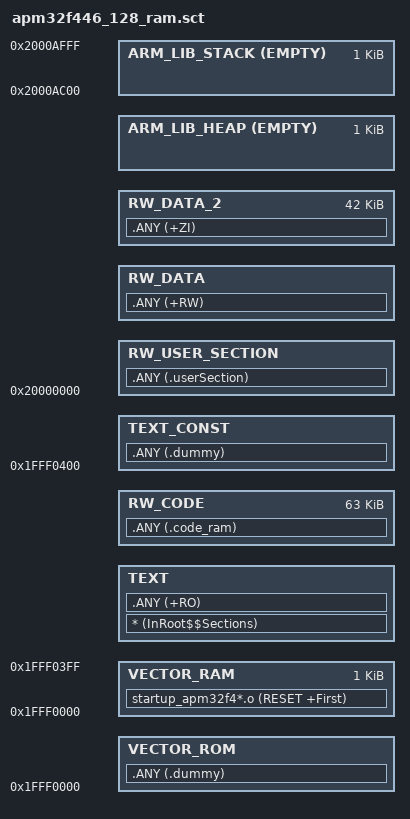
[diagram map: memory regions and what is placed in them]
#! armclang --target=arm-arm-none-eabi -mcpu=cortex-m4 -xc -E
/*
 * modified by ARM
 */

/*!
 * @file        apm32f446_64_ram.sct
 *
 * @brief       Linker file for the ARM Compiler
 *
 * @version     V1.0.0
 *
 * @date        2026-01-31
 *
 * @attention
 *
 *  Copyright (C) 2026 Geehy Semiconductor
 *
 *  You may not use this file except in compliance with the
 *  GEEHY COPYRIGHT NOTICE (GEEHY SOFTWARE PACKAGE LICENSE).
 *
 *  The program is only for reference, which is distributed in the hope
 *  that it will be useful and instructional for customers to develop
 *  their software. Unless required by applicable law or agreed to in
 *  writing, the program is distributed on an "AS IS" BASIS, WITHOUT
 *  ANY WARRANTY OR CONDITIONS OF ANY KIND, either express or implied.
 *  See the GEEHY SOFTWARE PACKAGE LICENSE for the governing permissions
 *  and limitations under the License.
 */

/**
 * Total SRAM: 128KB
 * SRAM_L (64KB): 0x1FFF0000 - 0x1FFFFFFF
 * SRAM_U (60KB): 0x20000000 - 0x2000EFFF
 *
 * Use 46KB for text: 0x1FFF0400 - 0x2000EFFF
 */
#define start_interrupts             0x1FFF0000
#define size_interrupts              0x00000400

#define start_text                   0x1FFF0000 + size_interrupts
#define size_text                    0x0000FC00

#define start_data2                 0x20000000
#define size_data2                  0x0000B000

/* Sizes */
#define Heap_Size                    0x0400
#define Stack_Size                   0x0400


LR_m_text start_interrupts start_data2+size_data2-start_interrupts {
  VECTOR_ROM start_interrupts 0x0 {
    .ANY (.dummy)
  }

  TEXT_CONST start_text  {
    .ANY (.dummy)
  }

  VECTOR_RAM start_interrupts size_interrupts {
    startup_apm32f4*.o (RESET +First)
  }

  TEXT +0 {
    * (InRoot$$Sections)
    .ANY (+RO)
  }

  RW_CODE +0 size_text {
    .ANY (.code_ram)
  }

  RW_USER_SECTION start_data2 ALIGN 0x4 {
    .ANY (.userSection)
  }

  RW_DATA +0 {
    .ANY (+RW)
  }

  RW_DATA_2 +0 size_data2-Stack_Size-Heap_Size {
    .ANY (+ZI)
  }

  ARM_LIB_HEAP ((ImageLimit(RW_DATA_2) == start_data2) ? start_data2 : +0) EMPTY Heap_Size {
  }

  ARM_LIB_STACK start_data2+size_data2 EMPTY -Stack_Size {
  }
}
